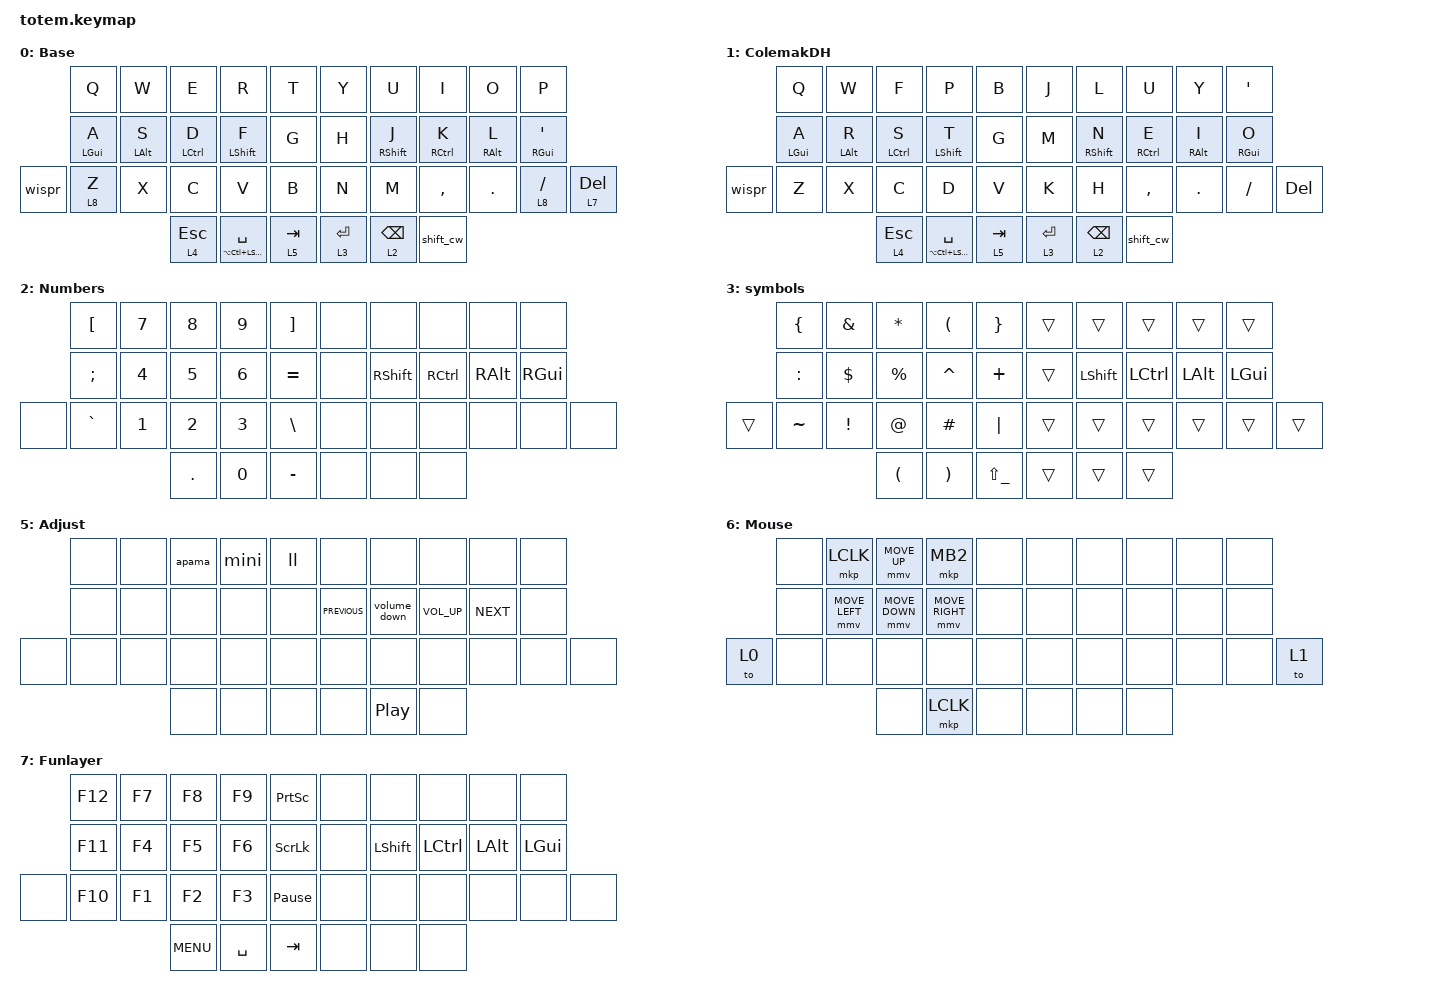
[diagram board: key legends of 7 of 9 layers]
//
//                                                        ▀▀▀▀▀     ▀▀▀▀▀          ▀▀█▀▀
//                                                        ▄▀▀▀▄  ▄  ▄▀▀▀▄  ▄  ▄▀▀▀▄  █  ▄▀▀▀▄
//                                                        █   █  █  █   █  █  █   █  █  █   █
//                                                         ▀▀▀   █   ▀▀▀   █   ▀▀▀   ▀   ▀▀▀
//                                                               █      ▄▄▄█▄▄▄    █   █  
//                                                               ▀      █  █  █     █▄█
//                                                             ▀▀▀▀▀    █  █  █      ▀
//                                                                      ▀  ▀  ▀
//
// ▄▄▄▄▄▄▄▄▄▄▄▄▄▄▄▄▄▄▄▄▄▄▄▄▄▄▄▄▄▄▄▄▄▄▄▄▄▄▄▄▄▄▄▄▄▄▄▄▄▄▄▄▄▄▄▄▄▄▄▄▄▄▄▄▄▄▄▄▄▄▄▄▄▄▄▄▄▄▄▄▄▄▄▄▄▄▄▄▄▄▄▄▄▄▄▄▄▄▄▄▄▄▄▄▄▄▄▄▄▄▄▄▄▄▄▄▄▄▄▄▄▄▄▄▄▄▄▄▄▄▄▄▄▄▄▄▄▄▄▄▄▄▄▄▄▄▄▄▄

#include <behaviors.dtsi>
#include <dt-bindings/zmk/keys.h>
#include <dt-bindings/zmk/pointing.h>
#include "zmk-helpers/helper.h"
#include "zmk-helpers/key-labels/totem.h"

#define Base        0
#define Nav         1
#define Sym         2
#define Fun         3
#define Game        4
#define Gameplus    5

&mt {
    quick-tap-ms = <100>;
    global-quick-tap;
    flavor = "tap-preferred";
    tapping-term-ms = <170>;
};

&lt {
    tapping-term-ms = <240>;
    flavor = "balanced";
    quick-tap-ms = <150>;
};

/ {
    behaviors {
        shift_cw: shift_cw {
            compatible = "zmk,behavior-tap-dance";
            label = "SHIFT_CW";
            #binding-cells = <0>;
            bindings = <&sk RSHFT>, <&caps_word>;

            tapping-term-ms = <300>;
        };

        volume_down: volume_down {
            compatible = "zmk,behavior-tap-dance";
            label = "VOLUME_DOWN";
            #binding-cells = <0>;
            bindings = <&kp C_VOL_DN>, <&kp C_VOL_DN>, <&kp C_MUTE>;
        };

        wispr: wispr {
            compatible = "zmk,behavior-tap-dance";
            label = "WISPR";
            #binding-cells = <0>;
            bindings = <&kp LSHFT>, <&sk F13>;
        };

        hml: hml {
            compatible = "zmk,behavior-hold-tap";
            label = "HML";
            bindings = <&kp>, <&kp>;

            #binding-cells = <2>;
            tapping-term-ms = <280>;
            require-prior-idle-ms = <150>;
            flavor = "balanced";
            hold-trigger-key-positions = <5 6 7 8 9 15 16 17 18 19 26 27 28 29 30 31 35 36 37>;
            hold-trigger-on-release;
        };

        hmr: hmr {
            compatible = "zmk,behavior-hold-tap";
            label = "HMR";
            bindings = <&kp>, <&kp>;

            #binding-cells = <2>;
            tapping-term-ms = <280>;
            require-prior-idle-ms = <150>;
            flavor = "balanced";
            hold-trigger-on-release;
            hold-trigger-key-positions = <0 1 2 3 4 10 11 12 13 14 20 21 22 23 24 25 32 33 34>;
        };
    };

    combos {
        compatible = "zmk,combos";

        colemak {
            bindings = <&to 1>;
            key-positions = <20 31>;
            layers = <0>;
        };

        qwerty {
            bindings = <&to 0>;
            key-positions = <20 31>;
            layers = <1>;
        };

        lsqbkt {
            bindings = <&kp LEFT_BRACKET>;
            key-positions = <0 10>;
        };

        rsqbkt {
            bindings = <&kp RBKT>;
            key-positions = <1 11>;
        };
    };

    macros {
        ll: ll {
            compatible = "zmk,behavior-macro";
            #binding-cells = <0>;
            bindings = <&kp N8 &kp N7 &kp N0 &kp N4 &kp N2 &kp N0 &kp LS(C) &kp A &kp L &kp N5 &kp N1 &kp N4 &kp EXCL>;
            label = "LL";
        };

        mini: crunch {
            compatible = "zmk,behavior-macro";
            #binding-cells = <0>;
            bindings = <&kp N2 &kp N5 &kp N0 &kp N1 &kp N2 &kp N5 &kp LS(E) &kp S &kp T &kp E &kp B &kp A &kp N &kp PRCNT>;
            label = "CRUNCH";
        };

        apama: new_macro {
            compatible = "zmk,behavior-macro";
            #binding-cells = <0>;
            bindings = <&none &kp E &kp S &kp T &kp E &kp B &kp A &kp N &kp LS(A) &kp P &kp A &kp M &kp A &kp N2 &kp N0 &kp N1 &kp N7 &kp EXCL>;
            label = "NEW_MACRO";
        };
    };

    keymap {
        compatible = "zmk,keymap";

        Base {
            display-name = "Base";
            bindings = <
        &kp Q            &kp W        &kp E         &kp R                    &kp T        &kp Y         &kp U            &kp I         &kp O        &kp P
        &hml LEFT_GUI A  &hml LALT S  &hml LCTRL D  &hml LSHFT F             &kp G        &kp H         &hmr RSHFT J     &hmr RCTRL K  &hmr RALT L  &hmr RGUI SQT
&wispr  &lt 8 Z          &kp X        &kp C         &kp V                    &kp B        &kp N         &kp M            &kp COMMA     &kp DOT      &lt 8 SLASH    &lt 7 DEL
                                      &lt 4 ESCAPE  &mt LA(LC(LSHFT)) SPACE  &lt 5 TAB    &lt 3 RETURN  &lt 2 BACKSPACE  &shift_cw
            >;
        };

        ColemakDH {
            bindings = <
        &kp Q            &kp W        &kp F         &kp P                    &kp B        &kp J        &kp L            &kp U         &kp Y        &kp SQT
        &hml LEFT_GUI A  &hml LALT R  &hml LCTRL S  &hml LSHFT T             &kp G        &kp M        &hmr RSHFT N     &hmr RCTRL E  &hmr RALT I  &hmr RGUI O
&wispr  &kp Z            &kp X        &kp C         &kp D                    &kp V        &kp K        &kp H            &kp COMMA     &kp DOT      &kp FSLH     &kp DELETE
                                      &lt 4 ESCAPE  &mt LA(LC(LSHFT)) SPACE  &lt 5 TAB    &lt 3 ENTER  &lt 2 BACKSPACE  &shift_cw
            >;
        };

        Numbers {
            bindings = <
       &kp LBKT   &kp N7  &kp N8   &kp N9  &kp RBKT     &none  &none      &none      &none     &none
       &kp SEMI   &kp N4  &kp N5   &kp N6  &kp EQUAL    &none  &kp RSHFT  &kp RCTRL  &kp RALT  &kp RGUI
&none  &kp GRAVE  &kp N1  &kp N2   &kp N3  &kp BSLH     &none  &none      &none      &none     &none     &none
                          &kp DOT  &kp N0  &kp MINUS    &none  &none      &none
            >;
        };

        symbols {
            bindings = <
        &kp LBRC   &kp AMPS  &kp STAR   &kp LPAR   &kp RBRC         &trans  &trans     &trans     &trans    &trans
        &kp COLON  &kp DLLR  &kp PRCNT  &kp CARET  &kp PLUS         &trans  &kp LSHFT  &kp LCTRL  &kp LALT  &kp LGUI
&trans  &kp TILDE  &kp EXCL  &kp AT     &kp POUND  &kp PIPE         &trans  &trans     &trans     &trans    &trans    &trans
                             &kp LPAR   &kp RPAR   &kp LS(UNDER)    &trans  &trans     &trans
            >;
        };

        Navigation {
            bindings = <
       &none     &none     &none      &none      &none    &kp HOME        &kp PAGE_DOWN  &kp PG_UP     &kp END    &kp DEL
       &kp LGUI  &kp LALT  &kp LCTRL  &kp LSHFT  &none    &kp LEFT_ARROW  &kp DOWN       &kp UP_ARROW  &kp RIGHT  &studio_unlock
&none  &none     &none     &none      &none      &none    &none           &none          &none         &none      &none           &none
                           &none      &none      &none    &none           &none
            >;
        };

        Adjust {
            bindings = <
       &none  &none  &apama  &mini  &ll      &none           &none             &none         &none       &none
       &none  &none  &none   &none  &none    &kp C_PREVIOUS  &volume_down      &kp C_VOL_UP  &kp C_NEXT  &none
&none  &none  &none  &none   &none  &none    &none           &none             &none         &none       &none  &none
                     &none   &none  &none    &none           &kp C_PLAY_PAUSE  &none
            >;
        };

        Mouse {
            bindings = <
       &none  &mkp LCLK       &mmv MOVE_UP    &mkp MB2         &none    &none  &none  &none  &none  &none
       &none  &mmv MOVE_LEFT  &mmv MOVE_DOWN  &mmv MOVE_RIGHT  &none    &none  &none  &none  &none  &none
&to 0  &none  &none           &none           &none            &none    &none  &none  &none  &none  &none  &to 1
                              &none           &mkp LCLK        &none    &none  &none  &none
            >;
        };

        Funlayer {
            bindings = <
       &kp F12  &kp F7  &kp F8      &kp F9     &kp PRINTSCREEN    &none  &none      &none      &none     &none
       &kp F11  &kp F4  &kp F5      &kp F6     &kp SCROLLLOCK     &none  &kp LSHFT  &kp LCTRL  &kp LALT  &kp LGUI
&none  &kp F10  &kp F1  &kp F2      &kp F3     &kp PAUSE_BREAK    &none  &none      &none      &none     &none     &none
                        &kp K_MENU  &kp SPACE  &kp TAB            &none  &none      &none
            >;
        };

        btn {
            bindings = <
       &kp RG(Z)  &kp RG(X)  &kp LG(C)  &kp LG(V)  &kp RS(RG(Z))    &kp RS(RG(Z))  &kp LG(V)  &kp LG(C)  &kp RG(X)  &kp RG(Z)
       &kp LCMD   &kp LALT   &kp LCTRL  &kp LSHFT  &none            &none          &kp LSHFT  &kp RCTRL  &kp RALT   &kp RCMD
&none  &kp RG(Z)  &kp RG(X)  &kp LG(C)  &kp LG(V)  &kp RS(RG(Z))    &kp RS(RG(Z))  &kp LG(V)  &kp LG(C)  &kp RG(X)  &kp RG(Z)  &none
                             &none      &none      &none            &none
            >;
        };
    };
};
